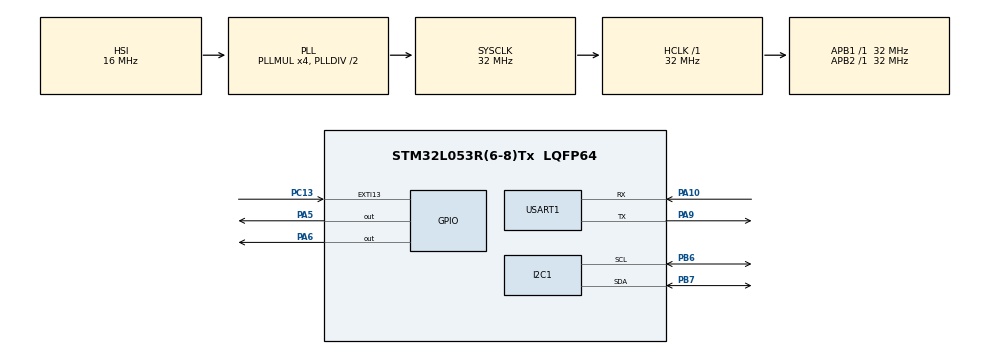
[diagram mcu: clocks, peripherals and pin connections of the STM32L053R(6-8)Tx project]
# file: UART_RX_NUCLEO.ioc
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ADC.ContinuousConvMode=ENABLE
ADC.DMAContinuousRequests=ENABLE
ADC.Resolution=ADC_RESOLUTION_10B
Dma.ADC.0.Direction=DMA_PERIPH_TO_MEMORY
Dma.ADC.0.Instance=DMA1_Channel2
Dma.ADC.0.MemDataAlignment=DMA_MDATAALIGN_HALFWORD
Dma.ADC.0.MemInc=DMA_MINC_ENABLE
Dma.ADC.0.Mode=DMA_NORMAL
Dma.ADC.0.PeriphDataAlignment=DMA_PDATAALIGN_HALFWORD
Dma.ADC.0.PeriphInc=DMA_PINC_DISABLE
Dma.ADC.0.Priority=DMA_PRIORITY_LOW
Dma.Request0=ADC
I2C1.Timing=0x00707CBB
Mcu.Family=STM32L0
Mcu.Name=STM32L053R(6-8)Tx
Mcu.Package=LQFP64
NVIC.DMA1_Channel2_3_IRQn=true\:0\:0\:false\:false\:true\:false\:true\:true
NVIC.EXTI4_15_IRQn=true\:0\:0\:false\:false\:true\:true\:true\:true
NVIC.I2C1_IRQn=true\:0\:0\:false\:false\:true\:true\:true\:true
NVIC.USART1_IRQn=true\:0\:0\:false\:false\:true\:true\:true\:true
PA10.Mode=Asynchronous
PA10.Signal=USART1_RX
PA5.Signal=GPIO_Output
PA6.Signal=GPIO_Output
PA9.Mode=Asynchronous
PA9.Signal=USART1_TX
PB6.Mode=I2C
PB6.Signal=I2C1_SCL
PB7.Mode=I2C
PB7.Signal=I2C1_SDA
PC13.Signal=GPXTI13
ProjectManager.HeapSize=0x200
ProjectManager.StackSize=0x400
ProjectManager.TargetToolchain=STM32CubeIDE
RCC.AHBFreq_Value=32000000
RCC.APB1Freq_Value=32000000
RCC.APB1TimFreq_Value=32000000
RCC.APB2Freq_Value=32000000
RCC.APB2TimFreq_Value=32000000
RCC.HCLKFreq_Value=32000000
RCC.HSE_VALUE=8000000
RCC.HSI16_VALUE=16000000
RCC.HSI48_VALUE=48000000
RCC.HSI_VALUE=16000000
RCC.LSE_VALUE=32768
RCC.MSI_VALUE=2097000
RCC.PLLMUL=RCC_PLLMUL_4
RCC.SYSCLKFreq_VALUE=32000000
RCC.SYSCLKSource=RCC_SYSCLKSOURCE_PLLCLK
RCC.VCOOutputFreq_Value=64000000
USART1.VirtualMode-Asynchronous=VM_ASYNC
VP_ADC_TempSens_Input.Mode=IN-TempSens
board=custom

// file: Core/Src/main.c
/* USER CODE BEGIN Header */
/* USER CODE END Header */
#include "main.h"

ADC_HandleTypeDef hadc;
DMA_HandleTypeDef hdma_adc;

I2C_HandleTypeDef hi2c1;

UART_HandleTypeDef huart1;

void SystemClock_Config(void);
static void MX_GPIO_Init(void);
static void MX_DMA_Init(void);
static void MX_ADC_Init(void);
static void MX_I2C1_Init(void);
static void MX_USART1_UART_Init(void);

uint8_t pdata[10];
int main(void)
{

  /* MCU Configuration--------------------------------------------------------*/

  /* Reset of all peripherals, Initializes the Flash interface and the Systick. */
  HAL_Init();

  /* Configure the system clock */
  SystemClock_Config();

  /* Initialize all configured peripherals */
  MX_GPIO_Init();
  MX_DMA_Init();
  MX_ADC_Init();
  MX_I2C1_Init();
  MX_USART1_UART_Init();
  /* USER CODE BEGIN 2 */
 // Scan_I2C_Address();
  /* USER CODE END 2 */

  /* Infinite loop */
  /* USER CODE BEGIN WHILE */
  HAL_UART_Receive_IT(&huart1, pdata, 10);
  while(1){
    /* USER CODE END WHILE */

    /* USER CODE BEGIN 3 */
	  HAL_UART_Receive_IT(&huart1, pdata, 10);

  }
  /* USER CODE END 3 */
}

void SystemClock_Config(void)
{
  RCC_OscInitTypeDef RCC_OscInitStruct = {0};
  RCC_ClkInitTypeDef RCC_ClkInitStruct = {0};
  RCC_PeriphCLKInitTypeDef PeriphClkInit = {0};

  /** Configure the main internal regulator output voltage
  */
  __HAL_PWR_VOLTAGESCALING_CONFIG(PWR_REGULATOR_VOLTAGE_SCALE1);

  /** Initializes the RCC Oscillators according to the specified parameters
  * in the RCC_OscInitTypeDef structure.
  */
  RCC_OscInitStruct.OscillatorType = RCC_OSCILLATORTYPE_HSI;
  RCC_OscInitStruct.HSIState = RCC_HSI_ON;
  RCC_OscInitStruct.HSICalibrationValue = RCC_HSICALIBRATION_DEFAULT;
  RCC_OscInitStruct.PLL.PLLState = RCC_PLL_ON;
  RCC_OscInitStruct.PLL.PLLSource = RCC_PLLSOURCE_HSI;
  RCC_OscInitStruct.PLL.PLLMUL = RCC_PLLMUL_4;
  RCC_OscInitStruct.PLL.PLLDIV = RCC_PLLDIV_2;
  if (HAL_RCC_OscConfig(&RCC_OscInitStruct) != HAL_OK)
  {
    Error_Handler();
  }

  /** Initializes the CPU, AHB and APB buses clocks
  */
  RCC_ClkInitStruct.ClockType = RCC_CLOCKTYPE_HCLK|RCC_CLOCKTYPE_SYSCLK
                              |RCC_CLOCKTYPE_PCLK1|RCC_CLOCKTYPE_PCLK2;
  RCC_ClkInitStruct.SYSCLKSource = RCC_SYSCLKSOURCE_PLLCLK;
  RCC_ClkInitStruct.AHBCLKDivider = RCC_SYSCLK_DIV1;
  RCC_ClkInitStruct.APB1CLKDivider = RCC_HCLK_DIV1;
  RCC_ClkInitStruct.APB2CLKDivider = RCC_HCLK_DIV1;

  if (HAL_RCC_ClockConfig(&RCC_ClkInitStruct, FLASH_LATENCY_1) != HAL_OK)
  {
    Error_Handler();
  }
  PeriphClkInit.PeriphClockSelection = RCC_PERIPHCLK_USART1|RCC_PERIPHCLK_I2C1;
  PeriphClkInit.Usart1ClockSelection = RCC_USART1CLKSOURCE_PCLK2;
  PeriphClkInit.I2c1ClockSelection = RCC_I2C1CLKSOURCE_PCLK1;
  if (HAL_RCCEx_PeriphCLKConfig(&PeriphClkInit) != HAL_OK)
  {
    Error_Handler();
  }
}

static void MX_ADC_Init(void)
{

  ADC_ChannelConfTypeDef sConfig = {0};

  /** Configure the global features of the ADC (Clock, Resolution, Data Alignment and number of conversion)
  */
  hadc.Instance = ADC1;
  hadc.Init.OversamplingMode = DISABLE;
  hadc.Init.ClockPrescaler = ADC_CLOCK_SYNC_PCLK_DIV2;
  hadc.Init.Resolution = ADC_RESOLUTION_10B;
  hadc.Init.SamplingTime = ADC_SAMPLETIME_1CYCLE_5;
  hadc.Init.ScanConvMode = ADC_SCAN_DIRECTION_FORWARD;
  hadc.Init.DataAlign = ADC_DATAALIGN_RIGHT;
  hadc.Init.ContinuousConvMode = ENABLE;
  hadc.Init.DiscontinuousConvMode = DISABLE;
  hadc.Init.ExternalTrigConvEdge = ADC_EXTERNALTRIGCONVEDGE_NONE;
  hadc.Init.ExternalTrigConv = ADC_SOFTWARE_START;
  hadc.Init.DMAContinuousRequests = ENABLE;
  hadc.Init.EOCSelection = ADC_EOC_SINGLE_CONV;
  hadc.Init.Overrun = ADC_OVR_DATA_PRESERVED;
  hadc.Init.LowPowerAutoWait = DISABLE;
  hadc.Init.LowPowerFrequencyMode = DISABLE;
  hadc.Init.LowPowerAutoPowerOff = DISABLE;
  if (HAL_ADC_Init(&hadc) != HAL_OK)
  {
    Error_Handler();
  }

  /** Configure for the selected ADC regular channel to be converted.
  */
  sConfig.Channel = ADC_CHANNEL_TEMPSENSOR;
  sConfig.Rank = ADC_RANK_CHANNEL_NUMBER;
  if (HAL_ADC_ConfigChannel(&hadc, &sConfig) != HAL_OK)
  {
    Error_Handler();
  }

}

static void MX_I2C1_Init(void)
{

  hi2c1.Instance = I2C1;
  hi2c1.Init.Timing = 0x00707CBB;
  hi2c1.Init.OwnAddress1 = 0;
  hi2c1.Init.AddressingMode = I2C_ADDRESSINGMODE_7BIT;
  hi2c1.Init.DualAddressMode = I2C_DUALADDRESS_DISABLE;
  hi2c1.Init.OwnAddress2 = 0;
  hi2c1.Init.OwnAddress2Masks = I2C_OA2_NOMASK;
  hi2c1.Init.GeneralCallMode = I2C_GENERALCALL_DISABLE;
  hi2c1.Init.NoStretchMode = I2C_NOSTRETCH_DISABLE;
  if (HAL_I2C_Init(&hi2c1) != HAL_OK)
  {
    Error_Handler();
  }

  /** Configure Analogue filter
  */
  if (HAL_I2CEx_ConfigAnalogFilter(&hi2c1, I2C_ANALOGFILTER_ENABLE) != HAL_OK)
  {
    Error_Handler();
  }

  /** Configure Digital filter
  */
  if (HAL_I2CEx_ConfigDigitalFilter(&hi2c1, 0) != HAL_OK)
  {
    Error_Handler();
  }

}

static void MX_USART1_UART_Init(void)
{

  huart1.Instance = USART1;
  huart1.Init.BaudRate = 115200;
  huart1.Init.WordLength = UART_WORDLENGTH_8B;
  huart1.Init.StopBits = UART_STOPBITS_1;
  huart1.Init.Parity = UART_PARITY_NONE;
  huart1.Init.Mode = UART_MODE_TX_RX;
  huart1.Init.HwFlowCtl = UART_HWCONTROL_NONE;
  huart1.Init.OverSampling = UART_OVERSAMPLING_16;
  huart1.Init.OneBitSampling = UART_ONE_BIT_SAMPLE_DISABLE;
  huart1.AdvancedInit.AdvFeatureInit = UART_ADVFEATURE_NO_INIT;
  if (HAL_UART_Init(&huart1) != HAL_OK)
  {
    Error_Handler();
  }

}

static void MX_DMA_Init(void)
{

  /* DMA controller clock enable */
  __HAL_RCC_DMA1_CLK_ENABLE();

  /* DMA interrupt init */
  /* DMA1_Channel2_3_IRQn interrupt configuration */
  HAL_NVIC_SetPriority(DMA1_Channel2_3_IRQn, 0, 0);
  HAL_NVIC_EnableIRQ(DMA1_Channel2_3_IRQn);

}

static void MX_GPIO_Init(void)
{
  GPIO_InitTypeDef GPIO_InitStruct = {0};

  /* GPIO Ports Clock Enable */
  __HAL_RCC_GPIOC_CLK_ENABLE();
  __HAL_RCC_GPIOA_CLK_ENABLE();
  __HAL_RCC_GPIOB_CLK_ENABLE();

  /*Configure GPIO pin Output Level */
  HAL_GPIO_WritePin(GPIOA, GPIO_PIN_5|GPIO_PIN_6, GPIO_PIN_RESET);

  /*Configure GPIO pin : PC13 */
  GPIO_InitStruct.Pin = GPIO_PIN_13;
  GPIO_InitStruct.Mode = GPIO_MODE_IT_RISING;
  GPIO_InitStruct.Pull = GPIO_NOPULL;
  HAL_GPIO_Init(GPIOC, &GPIO_InitStruct);

  /*Configure GPIO pins : PA5 PA6 */
  GPIO_InitStruct.Pin = GPIO_PIN_5|GPIO_PIN_6;
  GPIO_InitStruct.Mode = GPIO_MODE_OUTPUT_PP;
  GPIO_InitStruct.Pull = GPIO_NOPULL;
  GPIO_InitStruct.Speed = GPIO_SPEED_FREQ_LOW;
  HAL_GPIO_Init(GPIOA, &GPIO_InitStruct);

  /* EXTI interrupt init*/
  HAL_NVIC_SetPriority(EXTI4_15_IRQn, 0, 0);
  HAL_NVIC_EnableIRQ(EXTI4_15_IRQn);

}

void Error_Handler(void)
{
}
void HAL_UART_RxCpltCallback(UART_HandleTypeDef *huart)
{
  /* Prevent unused argument(s) compilation warning */
  UNUSED(huart);

  /* NOTE : This function should not be modified, when the callback is needed,
            the HAL_UART_RxCpltCallback can be implemented in the user file.
   */
}
